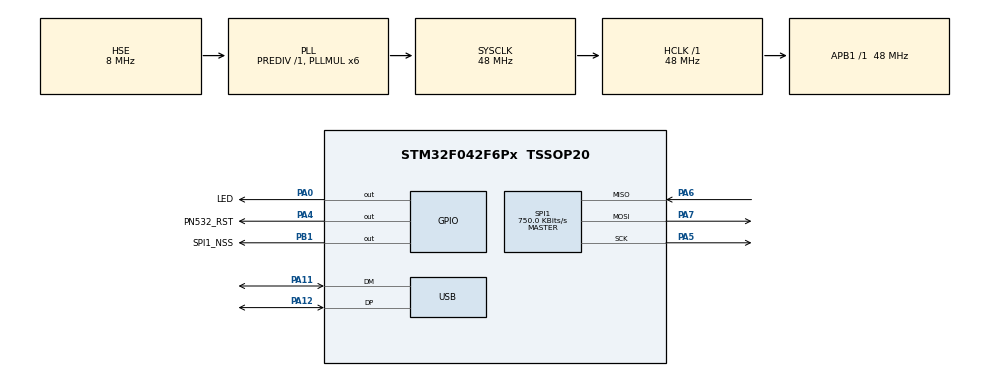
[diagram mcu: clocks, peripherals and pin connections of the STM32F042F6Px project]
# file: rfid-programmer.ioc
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Mcu.Family=STM32F0
Mcu.Name=STM32F042F6Px
Mcu.Package=TSSOP20
NVIC.USB_IRQn=true\:0\:0\:false\:false\:true\:false\:true\:true
PA0.GPIO_Label=LED
PA0.Signal=GPIO_Output
PA11.Mode=Device
PA11.Signal=USB_DM
PA12.Mode=Device
PA12.Signal=USB_DP
PA13.Mode=Serial_Wire
PA13.Signal=SYS_SWDIO
PA14.Mode=Serial_Wire
PA14.Signal=SYS_SWCLK
PA4.GPIO_Label=PN532_RST
PA4.Signal=GPIO_Output
PA5.Mode=Full_Duplex_Master
PA5.Signal=SPI1_SCK
PA6.Mode=Full_Duplex_Master
PA6.Signal=SPI1_MISO
PA7.Mode=Full_Duplex_Master
PA7.Signal=SPI1_MOSI
PB1.GPIO_Label=SPI1_NSS
PB1.PinState=GPIO_PIN_SET
PB1.Signal=GPIO_Output
PF0-OSC_IN.Mode=HSE-External-Oscillator
PF0-OSC_IN.Signal=RCC_OSC_IN
PF1-OSC_OUT.Mode=HSE-External-Oscillator
PF1-OSC_OUT.Signal=RCC_OSC_OUT
ProjectManager.HeapSize=0x200
ProjectManager.StackSize=0x400
ProjectManager.TargetToolchain=Makefile
RCC.AHBFreq_Value=48000000
RCC.APB1Freq_Value=48000000
RCC.APB1TimFreq_Value=48000000
RCC.HCLKFreq_Value=48000000
RCC.PLLMUL=RCC_PLL_MUL6
RCC.PLLSourceVirtual=RCC_PLLSOURCE_HSE
RCC.SYSCLKFreq_VALUE=48000000
RCC.SYSCLKSource=RCC_SYSCLKSOURCE_PLLCLK
SPI1.BaudRatePrescaler=SPI_BAUDRATEPRESCALER_64
SPI1.CalculateBaudRate=750.0 KBits/s
SPI1.DataSize=SPI_DATASIZE_8BIT
SPI1.Direction=SPI_DIRECTION_2LINES
SPI1.FirstBit=SPI_FIRSTBIT_LSB
SPI1.Mode=SPI_MODE_MASTER
SPI1.VirtualType=VM_MASTER
USB_DEVICE.APP_RX_DATA_SIZE=256
USB_DEVICE.APP_TX_DATA_SIZE=256
USB_DEVICE.CLASS_NAME_FS=CDC
USB_DEVICE.PRODUCT_STRING_CDC_FS=PN532
USB_DEVICE.VirtualMode=Cdc
USB_DEVICE.VirtualModeFS=Cdc_FS
VP_SYS_VS_PINREMAP.Mode=PINREMAP
VP_USB_DEVICE_VS_USB_DEVICE_CDC_FS.Mode=CDC_FS
board=custom

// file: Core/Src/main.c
/* USER CODE BEGIN Header */
/**
  ******************************************************************************
  * @file           : main.c
  * @brief          : Main program body
  ******************************************************************************
  * @attention
  *
  * Copyright (c) 2026 STMicroelectronics.
  * All rights reserved.
  *
  * This software is licensed under terms that can be found in the LICENSE file
  * in the root directory of this software component.
  * If no LICENSE file comes with this software, it is provided AS-IS.
  *
  ******************************************************************************
  */
/* USER CODE END Header */
#include "main.h"
#include "usb_device.h"

/* USER CODE BEGIN Includes */
#include "rfid.h"
/* USER CODE END Includes */

SPI_HandleTypeDef hspi1;

void SystemClock_Config(void);
static void MX_GPIO_Init(void);
static void MX_SPI1_Init(void);

int main(void)
{

  /* MCU Configuration--------------------------------------------------------*/

  /* Reset of all peripherals, Initializes the Flash interface and the Systick. */
  HAL_Init();

  /* Configure the system clock */
  SystemClock_Config();

  /* Initialize all configured peripherals */
  MX_GPIO_Init();
  MX_SPI1_Init();
  MX_USB_DEVICE_Init();
  /* USER CODE BEGIN 2 */
  HAL_GPIO_WritePin(LED_GPIO_Port, LED_Pin, 1);
  HAL_Delay(1000);
  HAL_GPIO_WritePin(LED_GPIO_Port, LED_Pin, 0);
  HAL_Delay(1000);
  /* USER CODE END 2 */

  /* Infinite loop */
  /* USER CODE BEGIN WHILE */
  while (1)
  {
	  execute_state();
    /* USER CODE END WHILE */

  }
}

void SystemClock_Config(void)
{
  RCC_OscInitTypeDef RCC_OscInitStruct = {0};
  RCC_ClkInitTypeDef RCC_ClkInitStruct = {0};
  RCC_PeriphCLKInitTypeDef PeriphClkInit = {0};

  /** Initializes the RCC Oscillators according to the specified parameters
  * in the RCC_OscInitTypeDef structure.
  */
  RCC_OscInitStruct.OscillatorType = RCC_OSCILLATORTYPE_HSI48|RCC_OSCILLATORTYPE_HSE;
  RCC_OscInitStruct.HSEState = RCC_HSE_ON;
  RCC_OscInitStruct.HSI48State = RCC_HSI48_ON;
  RCC_OscInitStruct.PLL.PLLState = RCC_PLL_ON;
  RCC_OscInitStruct.PLL.PLLSource = RCC_PLLSOURCE_HSE;
  RCC_OscInitStruct.PLL.PLLMUL = RCC_PLL_MUL6;
  RCC_OscInitStruct.PLL.PREDIV = RCC_PREDIV_DIV1;
  if (HAL_RCC_OscConfig(&RCC_OscInitStruct) != HAL_OK)
  {
    Error_Handler();
  }

  /** Initializes the CPU, AHB and APB buses clocks
  */
  RCC_ClkInitStruct.ClockType = RCC_CLOCKTYPE_HCLK|RCC_CLOCKTYPE_SYSCLK
                              |RCC_CLOCKTYPE_PCLK1;
  RCC_ClkInitStruct.SYSCLKSource = RCC_SYSCLKSOURCE_PLLCLK;
  RCC_ClkInitStruct.AHBCLKDivider = RCC_SYSCLK_DIV1;
  RCC_ClkInitStruct.APB1CLKDivider = RCC_HCLK_DIV1;

  if (HAL_RCC_ClockConfig(&RCC_ClkInitStruct, FLASH_LATENCY_1) != HAL_OK)
  {
    Error_Handler();
  }
  PeriphClkInit.PeriphClockSelection = RCC_PERIPHCLK_USB;
  PeriphClkInit.UsbClockSelection = RCC_USBCLKSOURCE_HSI48;

  if (HAL_RCCEx_PeriphCLKConfig(&PeriphClkInit) != HAL_OK)
  {
    Error_Handler();
  }
}

static void MX_SPI1_Init(void)
{

  /* SPI1 parameter configuration*/
  hspi1.Instance = SPI1;
  hspi1.Init.Mode = SPI_MODE_MASTER;
  hspi1.Init.Direction = SPI_DIRECTION_2LINES;
  hspi1.Init.DataSize = SPI_DATASIZE_8BIT;
  hspi1.Init.CLKPolarity = SPI_POLARITY_LOW;
  hspi1.Init.CLKPhase = SPI_PHASE_1EDGE;
  hspi1.Init.NSS = SPI_NSS_SOFT;
  hspi1.Init.BaudRatePrescaler = SPI_BAUDRATEPRESCALER_64;
  hspi1.Init.FirstBit = SPI_FIRSTBIT_LSB;
  hspi1.Init.TIMode = SPI_TIMODE_DISABLE;
  hspi1.Init.CRCCalculation = SPI_CRCCALCULATION_DISABLE;
  hspi1.Init.CRCPolynomial = 7;
  hspi1.Init.CRCLength = SPI_CRC_LENGTH_DATASIZE;
  hspi1.Init.NSSPMode = SPI_NSS_PULSE_ENABLE;
  if (HAL_SPI_Init(&hspi1) != HAL_OK)
  {
    Error_Handler();
  }

}

static void MX_GPIO_Init(void)
{
  GPIO_InitTypeDef GPIO_InitStruct = {0};

  /* GPIO Ports Clock Enable */
  __HAL_RCC_GPIOF_CLK_ENABLE();
  __HAL_RCC_GPIOA_CLK_ENABLE();
  __HAL_RCC_GPIOB_CLK_ENABLE();

  /*Configure GPIO pin Output Level */
  HAL_GPIO_WritePin(GPIOA, LED_Pin|PN532_RST_Pin, GPIO_PIN_RESET);

  /*Configure GPIO pin Output Level */
  HAL_GPIO_WritePin(SPI1_NSS_GPIO_Port, SPI1_NSS_Pin, GPIO_PIN_SET);

  /*Configure GPIO pins : LED_Pin PN532_RST_Pin */
  GPIO_InitStruct.Pin = LED_Pin|PN532_RST_Pin;
  GPIO_InitStruct.Mode = GPIO_MODE_OUTPUT_PP;
  GPIO_InitStruct.Pull = GPIO_NOPULL;
  GPIO_InitStruct.Speed = GPIO_SPEED_FREQ_LOW;
  HAL_GPIO_Init(GPIOA, &GPIO_InitStruct);

  /*Configure GPIO pin : SPI1_NSS_Pin */
  GPIO_InitStruct.Pin = SPI1_NSS_Pin;
  GPIO_InitStruct.Mode = GPIO_MODE_OUTPUT_PP;
  GPIO_InitStruct.Pull = GPIO_NOPULL;
  GPIO_InitStruct.Speed = GPIO_SPEED_FREQ_LOW;
  HAL_GPIO_Init(SPI1_NSS_GPIO_Port, &GPIO_InitStruct);

}

void Error_Handler(void)
{
  __disable_irq();
  while (1)
  {
  }
}
